# hsm_sec_secure register map
Vendor: Texas Instruments
Peripheral module from a debugger description file (folder CC35X1E).
Registers are 32-bit, access per field, reset 0x0 unless marked. A register's access mark holds for its fields unless they carry their own. Offsets are as the file gives them; lines under a group give offsets from that group; [hi:lo] are bit positions; {n}, {i} and the like mark numbered series; 'fields as' and 'values as' point back to an identical list; <NAME> marks a mode.

## hsm_sec_secure
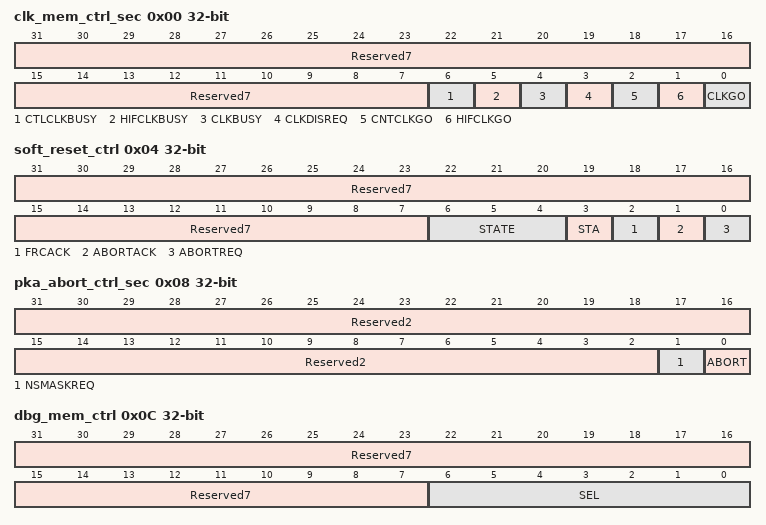
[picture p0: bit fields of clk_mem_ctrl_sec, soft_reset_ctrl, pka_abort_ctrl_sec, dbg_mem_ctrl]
0x00 clk_mem_ctrl_sec — Clock Control Secured Register. This register is used for enabling clock to the module.
  [31:7] Reserved7 ro — Reads to this field return zero, writes to this field are ignored.
  [6] CTLCLKBUSY ro — When 1b, indicates that the counter clock domain is active. This signal is always asserted (set to '1'), except when the counter module is in reset (ctr_reset_n set to '0').
  [5] HIFCLKBUSY ro — When 1b indicates the Host interface is active and busy with Host bus transfers.
  [4] CLKBUSY ro — when 1b, indicates that the module is active and busy with processing data and tokens.
  [3] CLKDISREQ rw — This bit is set to disable all clock sources.
    1=DIS (Write 1 to disable clock)
  [2] CNTCLKGO rw — Write this bit to enable counter clock
    0=DIS (Write 0 to disable clock); 1=EN (Write 1 to enable clock)
  [1] HIFCLKGO rw — Write this bit to enable host interface clock
    values as CNTCLKGO
  [0] CLKGO rw — Write this bit to enable clock to the module
    values as CNTCLKGO
0x04 soft_reset_ctrl — Soft Reset Control. This register is used for controlling soft reset mechanism.
  [31:7] Reserved7 ro — Reads to this field return zero, writes to this field are ignored.
  [6:4] STATE ro — It indicates state of soft reset assertion.
    0=IDLE (soft reset is not requested); 1=REQ (Soft reset is requested); 2=ACK (Soft reset is acknowledged.); 3=ASSERT (Soft reset can be asserted); 4=SET (soft reset is set)
  [3] STA ro — When 1b, soft reset is asserted to the module
  [2] FRCACK wo — Write 1b, to forcely assert soft reset without waiting for abort acknowledge from EIP.
    1=EN (To force soft reset)
  [1] ABORTACK ro — when 1b, indicates abort request is acknowledged by EIP and soft reset is asserted
  [0] ABORTREQ wo — Write this bit to request soft reset. It is a write-clear or auto clear register.
    1=REQ (To enable Abort request)
0x08 pka_abort_ctrl_sec — PKA Abort Control Secured Register. This register is used for aborting PKA operation.
  [31:2] Reserved2 ro — Reads to this field return zero, writes to this field are ignored.
  [1] NSMASKREQ rw — This bit is used to mask PKA abort request generated by non-secure controller.
    1=MASK (Mask request)
  [0] ABORT rw — Write 1 to Abort.
    1=ABORT (Write 1 to this bit to abort PKA operation)
0x0C dbg_mem_ctrl — Debug Control. This register is used for HSM memory and asset debug through OCP only if TI debug access is enabled
  [31:7] Reserved7 ro — Reads to this field return zero, writes to this field are ignored.
  [6:0] SEL rw — This register enables debug through OCP. To enable FIFO0 , bit0 should be set. To enable FIFO1 , bit1 should be set. To enable MBIN , bit2 should be set. To enable MBOUT, bit3 should be set. To enable OTP , bit4 should be set. To enable DRAM , bit5 should be set. To enable PROM , bit6 should be set.
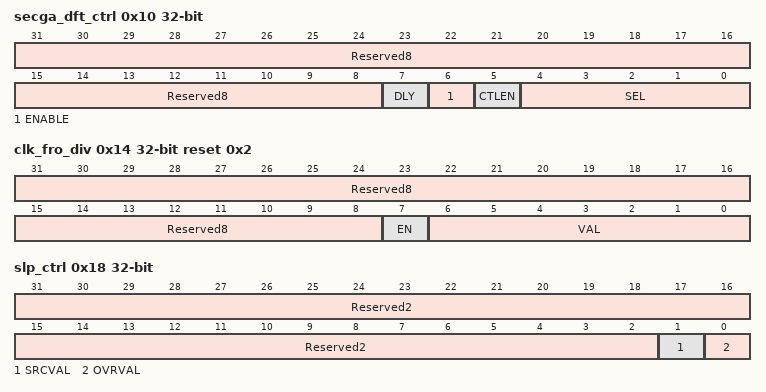
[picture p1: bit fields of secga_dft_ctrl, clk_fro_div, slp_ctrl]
0x10 secga_dft_ctrl — DFT Control. This register is used for enabling FRO controls if TI test access is enabled
  [31:8] Reserved8 ro — Reads to this field return zero, writes to this field are ignored.
  [7] DLY rw — Delay chain length selection for FRO selected by tst_fro_select. This input should only be changed while tst_fro_enable is LOW.
  [6] ENABLE rw — Active HIGH enable signal for FRO selected by tst_fro_select
  [5] CTLEN rw — Active HIGH enable signal for FRO characterization (enables the tst_fro_select, tst_fro_enable and tst_fro_delay inputs). This is a combinatorial function. The TRNG module clocks do not need to run for this to work.
  [4:0] SEL rw — FRO selection input. A selected FRO will have its fro_testin input forced low. Valid value to select FRO's is 0-7.
0x14 clk_fro_div reset 0x2 — Clock FRO Divide Configuration. This register is used for controlling FRO clock measurements.
  [31:8] Reserved8 ro — Reads to this field return zero, writes to this field are ignored.
  [7] EN rw — It is write enable signal used for loading division value onto divider. It should be disable and re-enable after changing the mem_value
  [6:0] VAL rw — It is used for dividing FRO clock withe the division value specified by this register. Division value should be from 2-80.
0x18 slp_ctrl — Sleep Control.
  [31:2] Reserved2 ro — Reads to this field return zero, writes to this field are ignored.
  [1] SRCVAL rw — power_mode_in source select MMR 0-power_mode_in comes from logic 1-power_mode_in comes from mem_slp_ovr_val
  [0] OVRVAL rw — power_mode_in override value by FW. FW can set to 1 after cold boot
